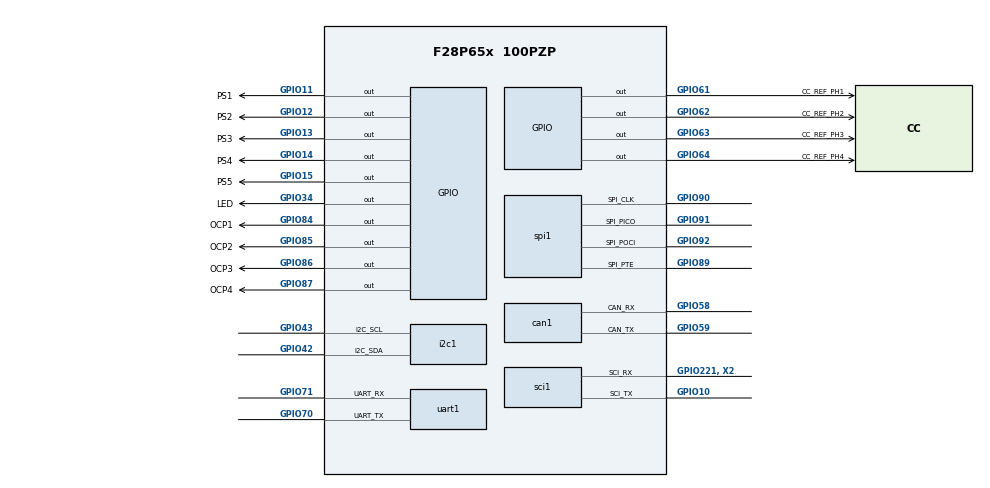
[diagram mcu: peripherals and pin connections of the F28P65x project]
/**
 * @cliArgs --device "F28P65x" --part "F28P65x_100PZP" --package "100PZP" --context "CPU1" --product "C2000WARE@6.00.01.00"
 * @versions {"tool":"1.26.0+4407"}
 */

/**
 * Import the modules used in this configuration.
 */
const adc              = scripting.addModule("/driverlib/adc.js", {}, false);
const adc1             = adc.addInstance();
const adc2             = adc.addInstance();
const adc3             = adc.addInstance();
const led              = scripting.addModule("/driverlib/board_components/led", {}, false);
const led1             = led.addInstance();
const can              = scripting.addModule("/driverlib/can.js", {}, false);
const can1             = can.addInstance();
const dac              = scripting.addModule("/driverlib/dac.js", {}, false);
const dac1             = dac.addInstance();
const dac2             = dac.addInstance();
const epwm             = scripting.addModule("/driverlib/epwm.js", {}, false);
const epwm1            = epwm.addInstance();
const epwm2            = epwm.addInstance();
const epwm3            = epwm.addInstance();
const epwm4            = epwm.addInstance();
const gpio             = scripting.addModule("/driverlib/gpio.js", {}, false);
const gpio2            = gpio.addInstance();
const gpio3            = gpio.addInstance();
const gpio4            = gpio.addInstance();
const gpio5            = gpio.addInstance();
const gpio6            = gpio.addInstance();
const gpio7            = gpio.addInstance();
const gpio8            = gpio.addInstance();
const gpio9            = gpio.addInstance();
const gpio10           = gpio.addInstance();
const gpio11           = gpio.addInstance();
const gpio12           = gpio.addInstance();
const gpio13           = gpio.addInstance();
const gpio14           = gpio.addInstance();
const gpio15           = gpio.addInstance();
const gpio16           = gpio.addInstance();
const gpio17           = gpio.addInstance();
const i2c              = scripting.addModule("/driverlib/i2c.js", {}, false);
const i2c1             = i2c.addInstance();
const inputxbar_input  = scripting.addModule("/driverlib/inputxbar_input.js", {}, false);
const inputxbar_input1 = inputxbar_input.addInstance();
const inputxbar_input2 = inputxbar_input.addInstance();
const inputxbar_input3 = inputxbar_input.addInstance();
const inputxbar_input4 = inputxbar_input.addInstance();
const inputxbar_input5 = inputxbar_input.addInstance();
const sci              = scripting.addModule("/driverlib/sci.js", {}, false);
const sci1             = sci.addInstance();
const spi              = scripting.addModule("/driverlib/spi.js", {}, false);
const spi1             = spi.addInstance();
const uart             = scripting.addModule("/driverlib/uart.js", {}, false);
const uart1            = uart.addInstance();
const uart2            = uart.addInstance();

/**
 * Write custom configuration values to the imported modules.
 */
adc1.$name             = "myADC0";
adc1.adcClockPrescaler = "ADC_CLK_DIV_3_5";
adc1.soc0SampleWindow  = 15;
adc1.soc1SampleWindow  = 15;
adc1.soc2SampleWindow  = 15;
adc1.soc3SampleWindow  = 15;
adc1.soc4SampleWindow  = 15;
adc1.soc0Channel       = "ADC_CH_ADCIN1";
adc1.soc1Channel       = "ADC_CH_ADCIN2";
adc1.soc2Channel       = "ADC_CH_ADCIN3";
adc1.soc3Channel       = "ADC_CH_ADCIN4";
adc1.soc4Channel       = "ADC_CH_ADCIN5";
adc1.enabledSOCs       = ["ADC_SOC_NUMBER0","ADC_SOC_NUMBER1","ADC_SOC_NUMBER2","ADC_SOC_NUMBER3","ADC_SOC_NUMBER4","ADC_SOC_NUMBER5","ADC_SOC_NUMBER6","ADC_SOC_NUMBER7"];
adc1.soc5Channel       = "ADC_CH_ADCIN6";
adc1.soc5SampleWindow  = 15;
adc1.soc6SampleWindow  = 15;
adc1.soc7SampleWindow  = 15;
adc1.soc6Channel       = "ADC_CH_ADCIN10";
adc1.soc7Channel       = "ADC_CH_ADCIN11";

adc2.$name             = "myADC1";
adc2.adcBase           = "ADCB_BASE";
adc2.adcClockPrescaler = "ADC_CLK_DIV_3_5";
adc2.soc0SampleWindow  = 15;
adc2.soc1SampleWindow  = 15;
adc2.soc2SampleWindow  = 15;
adc2.soc3SampleWindow  = 15;
adc2.soc1Channel       = "ADC_CH_ADCIN2";
adc2.soc2Channel       = "ADC_CH_ADCIN3";
adc2.soc3Channel       = "ADC_CH_ADCIN6";
adc2.enabledSOCs       = ["ADC_SOC_NUMBER0","ADC_SOC_NUMBER1","ADC_SOC_NUMBER2","ADC_SOC_NUMBER3","ADC_SOC_NUMBER4"];
adc2.soc4Channel       = "ADC_CH_ADCIN7";
adc2.soc4SampleWindow  = 15;

adc3.$name             = "myADC2";
adc3.adcClockPrescaler = "ADC_CLK_DIV_4_0";
adc3.adcResolutionMode = "ADC_RESOLUTION_16BIT";
adc3.adcSignalMode     = "ADC_MODE_DIFFERENTIAL";
adc3.enabledSOCs       = ["ADC_SOC_NUMBER0","ADC_SOC_NUMBER1","ADC_SOC_NUMBER2","ADC_SOC_NUMBER3"];
adc3.soc0Channel       = "ADC_CH_ADCIN0_ADCIN1";
adc3.soc0SampleWindow  = 65;
adc3.soc1Channel       = "ADC_CH_ADCIN2_ADCIN3";
adc3.soc1SampleWindow  = 65;
adc3.soc2Channel       = "ADC_CH_ADCIN4_ADCIN5";
adc3.soc2SampleWindow  = 65;
adc3.soc3Channel       = "ADC_CH_ADCIN14_ADCIN15";
adc3.soc3SampleWindow  = 65;
adc3.adcBase           = "ADCC_BASE";

led1.$name                = "LED";
led1.gpio.gpioPin.$assign = "GPIO34";

can1.$name                 = "myCAN0";
can1.can.$assign           = "CANA";
can1.can.can_rxPin.$assign = "GPIO58";
can1.can.can_txPin.$assign = "GPIO59";

const divider8       = system.clockTree["EPWMCLKDIV"];
divider8.divideValue = 1;

dac1.$name            = "myDAC0";
dac1.referenceVoltage = "DAC_REF_ADC_VREFHI";
dac1.enableOutput     = true;

dac2.$name            = "myDAC1";
dac2.dacBase          = "DACC_BASE";
dac2.enableOutput     = true;
dac2.referenceVoltage = "DAC_REF_ADC_VREFHI";

const analog  = scripting.addModule("/driverlib/analog.js", {}, false);
const analog1 = analog.addInstance({}, false);
analog1.$name = "myANALOGPinMux0";
adc1.analog   = analog1;
adc2.analog   = analog1;
adc3.analog   = analog1;
dac1.analog   = analog1;
dac2.analog   = analog1;

epwm1.$name                                                    = "myEPWM0";
epwm1.epwmTimebase_hsClockDiv                                  = "EPWM_HSCLOCK_DIVIDER_1";
epwm1.epwmTimebase_counterMode                                 = "EPWM_COUNTER_MODE_UP";
epwm1.epwmTimebase_period                                      = 10000;
epwm1.epwmCounterCompare_cmpA                                  = 5000;
epwm1.epwmActionQualifier_EPWM_AQ_OUTPUT_A_ON_TIMEBASE_ZERO    = "EPWM_AQ_OUTPUT_HIGH";
epwm1.epwmActionQualifier_EPWM_AQ_OUTPUT_A_ON_TIMEBASE_UP_CMPA = "EPWM_AQ_OUTPUT_LOW";
epwm1.epwmActionQualifier_EPWM_AQ_OUTPUT_B_ON_TIMEBASE_ZERO    = "EPWM_AQ_OUTPUT_HIGH";
epwm1.epwmActionQualifier_EPWM_AQ_OUTPUT_B_ON_TIMEBASE_UP_CMPB = "EPWM_AQ_OUTPUT_LOW";
epwm1.epwmCounterCompare_cmpB                                  = 5000;
epwm1.epwm.$assign                                             = "EPWM1";

epwm2.$name                                                    = "myEPWM1";
epwm2.copyUse                                                  = true;
epwm2.copyFrom                                                 = "myEPWM0";
epwm2.epwmTimebase_hsClockDiv                                  = "EPWM_HSCLOCK_DIVIDER_1";
epwm2.epwmTimebase_period                                      = 10000;
epwm2.epwmTimebase_counterMode                                 = "EPWM_COUNTER_MODE_UP";
epwm2.epwmCounterCompare_cmpA                                  = 5000;
epwm2.epwmCounterCompare_cmpB                                  = 5000;
epwm2.epwmActionQualifier_EPWM_AQ_OUTPUT_A_ON_TIMEBASE_ZERO    = "EPWM_AQ_OUTPUT_HIGH";
epwm2.epwmActionQualifier_EPWM_AQ_OUTPUT_A_ON_TIMEBASE_UP_CMPA = "EPWM_AQ_OUTPUT_LOW";
epwm2.epwmActionQualifier_EPWM_AQ_OUTPUT_B_ON_TIMEBASE_ZERO    = "EPWM_AQ_OUTPUT_HIGH";
epwm2.epwmActionQualifier_EPWM_AQ_OUTPUT_B_ON_TIMEBASE_UP_CMPB = "EPWM_AQ_OUTPUT_LOW";
epwm2.epwm.$assign                                             = "EPWM2";

epwm3.$name                                                    = "myEPWM2";
epwm3.copyUse                                                  = true;
epwm3.copyFrom                                                 = "myEPWM1";
epwm3.epwmTimebase_hsClockDiv                                  = "EPWM_HSCLOCK_DIVIDER_1";
epwm3.epwmTimebase_period                                      = 10000;
epwm3.epwmTimebase_counterMode                                 = "EPWM_COUNTER_MODE_UP";
epwm3.epwmCounterCompare_cmpA                                  = 5000;
epwm3.epwmCounterCompare_cmpB                                  = 5000;
epwm3.epwmActionQualifier_EPWM_AQ_OUTPUT_A_ON_TIMEBASE_ZERO    = "EPWM_AQ_OUTPUT_HIGH";
epwm3.epwmActionQualifier_EPWM_AQ_OUTPUT_A_ON_TIMEBASE_UP_CMPA = "EPWM_AQ_OUTPUT_LOW";
epwm3.epwmActionQualifier_EPWM_AQ_OUTPUT_B_ON_TIMEBASE_ZERO    = "EPWM_AQ_OUTPUT_HIGH";
epwm3.epwmActionQualifier_EPWM_AQ_OUTPUT_B_ON_TIMEBASE_UP_CMPB = "EPWM_AQ_OUTPUT_LOW";
epwm3.epwm.$assign                                             = "EPWM3";

epwm4.$name                                                    = "myEPWM3";
epwm4.copyUse                                                  = true;
epwm4.copyFrom                                                 = "myEPWM1";
epwm4.epwmTimebase_hsClockDiv                                  = "EPWM_HSCLOCK_DIVIDER_1";
epwm4.epwmTimebase_period                                      = 10000;
epwm4.epwmTimebase_counterMode                                 = "EPWM_COUNTER_MODE_UP";
epwm4.epwmCounterCompare_cmpA                                  = 5000;
epwm4.epwmCounterCompare_cmpB                                  = 5000;
epwm4.epwmActionQualifier_EPWM_AQ_OUTPUT_A_ON_TIMEBASE_ZERO    = "EPWM_AQ_OUTPUT_HIGH";
epwm4.epwmActionQualifier_EPWM_AQ_OUTPUT_A_ON_TIMEBASE_UP_CMPA = "EPWM_AQ_OUTPUT_LOW";
epwm4.epwmActionQualifier_EPWM_AQ_OUTPUT_B_ON_TIMEBASE_ZERO    = "EPWM_AQ_OUTPUT_HIGH";
epwm4.epwmActionQualifier_EPWM_AQ_OUTPUT_B_ON_TIMEBASE_UP_CMPB = "EPWM_AQ_OUTPUT_LOW";
epwm4.epwm.$assign                                             = "EPWM4";

gpio2.$name           = "PS1";
gpio2.padConfig       = "PULLUP";
gpio2.qualMode        = "GPIO_QUAL_ASYNC";
gpio2.gpioPin.$assign = "GPIO11";

gpio3.$name           = "PS3";
gpio3.padConfig       = "PULLUP";
gpio3.gpioPin.$assign = "GPIO13";

gpio4.$name           = "PS4";
gpio4.padConfig       = "PULLUP";
gpio4.gpioPin.$assign = "GPIO14";

gpio5.$name           = "PS5";
gpio5.padConfig       = "PULLUP";
gpio5.gpioPin.$assign = "GPIO15";

gpio6.$name           = "OCP1";
gpio6.padConfig       = "PULLUP";
gpio6.qualMode        = "GPIO_QUAL_ASYNC";
gpio6.gpioPin.$assign = "GPIO84";

gpio7.$name           = "OCP2";
gpio7.padConfig       = "PULLUP";
gpio7.qualMode        = "GPIO_QUAL_ASYNC";
gpio7.gpioPin.$assign = "GPIO85";

gpio8.$name           = "OCP3";
gpio8.padConfig       = "PULLUP";
gpio8.qualMode        = "GPIO_QUAL_ASYNC";
gpio8.gpioPin.$assign = "GPIO86";

gpio9.$name           = "OCP4";
gpio9.padConfig       = "PULLUP";
gpio9.qualMode        = "GPIO_QUAL_ASYNC";
gpio9.gpioPin.$assign = "GPIO87";

gpio10.$name           = "PS2";
gpio10.padConfig       = "PULLUP";
gpio10.qualMode        = "GPIO_QUAL_ASYNC";
gpio10.gpioPin.$assign = "GPIO12";

gpio11.$name           = "CC_REF_PH1";
gpio11.padConfig       = "PULLUP";
gpio11.gpioPin.$assign = "GPIO61";

gpio12.$name           = "CC_REF_PH2";
gpio12.padConfig       = "PULLUP";
gpio12.gpioPin.$assign = "GPIO62";

gpio13.$name           = "CC_REF_PH3";
gpio13.padConfig       = "PULLUP";
gpio13.gpioPin.$assign = "GPIO63";

gpio14.$name           = "CC_REF_PH4";
gpio14.padConfig       = "PULLUP";
gpio14.gpioPin.$assign = "GPIO64";

gpio15.$name             = "RELAY";
gpio15.writeInitialValue = true;
gpio15.direction         = "GPIO_DIR_MODE_OUT";

gpio16.$name     = "PFC";
gpio16.direction = "GPIO_DIR_MODE_OUT";

gpio17.$name = "myGPIO0";

i2c1.$name                  = "myI2C0";
i2c1.i2c.$assign            = "I2CA";
i2c1.i2c.i2c_sdaPin.$assign = "GPIO42";
i2c1.i2c.i2c_sclPin.$assign = "GPIO43";

inputxbar_input1.$name          = "myINPUTXBARINPUT0";
inputxbar_input1.inputxbarInput = "XBAR_INPUT4";
inputxbar_input1.inputxbarGpio  = "GPIO11";

inputxbar_input2.$name          = "myINPUTXBARINPUT1";
inputxbar_input2.inputxbarInput = "XBAR_INPUT5";
inputxbar_input2.inputxbarGpio  = "GPIO12";

inputxbar_input3.$name          = "myINPUTXBARINPUT2";
inputxbar_input3.inputxbarInput = "XBAR_INPUT6";
inputxbar_input3.inputxbarGpio  = "GPIO13";

inputxbar_input4.$name          = "myINPUTXBARINPUT3";
inputxbar_input4.inputxbarInput = "XBAR_INPUT13";
inputxbar_input4.inputxbarGpio  = "GPIO14";

inputxbar_input5.$name          = "myINPUTXBARINPUT4";
inputxbar_input5.inputxbarInput = "XBAR_INPUT14";
inputxbar_input5.inputxbarGpio  = "GPIO15";

sci1.$name                 = "mySCI0";
sci1.sci.$assign           = "SCIB";
sci1.sci.sci_rxPin.$assign = "GPIO221, X2";
sci1.sci.sci_txPin.$assign = "GPIO10";
sci1.rxQual.$name          = "myGPIOQUAL0";
sci1.txQual.$name          = "myGPIOQUAL1";

spi1.$name                   = "mySPI0";
spi1.spi.$assign             = "SPID";
spi1.spi.spi_picoPin.$assign = "GPIO91";
spi1.spi.spi_pociPin.$assign = "GPIO92";
spi1.spi.spi_clkPin.$assign  = "GPIO90";
spi1.spi.spi_ptePin.$assign  = "GPIO89";
spi1.picoQual.$name          = "myGPIOQUAL6";
spi1.pociQual.$name          = "myGPIOQUAL7";
spi1.clkQual.$name           = "myGPIOQUAL8";
spi1.pteQual.$name           = "myGPIOQUAL9";

uart1.$name                   = "myUART0";
uart1.uart.$assign            = "UARTB";
uart1.uart.uart_txPin.$assign = "GPIO70";
uart1.uart.uart_rxPin.$assign = "GPIO71";
uart1.txQual.$name            = "myGPIOQUAL2";
uart1.rxQual.$name            = "myGPIOQUAL3";

uart2.$name        = "myUART1";
uart2.uart.$assign = "UARTA";
uart2.txQual.$name = "myGPIOQUAL4";
uart2.rxQual.$name = "myGPIOQUAL5";

/**
 * Pinmux solution for unlocked pins/peripherals. This ensures that minor changes to the automatic solver in a future
 * version of the tool will not impact the pinmux you originally saw.  These lines can be completely deleted in order to
 * re-solve from scratch.
 */
analog1.analog.$suggestSolution                    = "ANALOG";
analog1.analog["a0/daca_outPin"].$suggestSolution  = "A0/DACA_OUT";
analog1.analog.a1Pin.$suggestSolution              = "A1";
analog1.analog["a10, gpio213Pin"].$suggestSolution = "A10, GPIO213";
analog1.analog["a11, gpio214Pin"].$suggestSolution = "A11, GPIO214";
analog1.analog["a14/b14/c14Pin"].$suggestSolution  = "A14/B14/C14";
analog1.analog["a15/b15/c15Pin"].$suggestSolution  = "A15/B15/C15";
analog1.analog.a2Pin.$suggestSolution              = "A2";
analog1.analog.a3Pin.$suggestSolution              = "A3";
analog1.analog.a4Pin.$suggestSolution              = "A4";
analog1.analog.a5Pin.$suggestSolution              = "A5";
analog1.analog["a6, gpio209Pin"].$suggestSolution  = "A6, GPIO209";
analog1.analog["b0/vdacPin"].$suggestSolution      = "B0/VDAC";
analog1.analog["b1/dacc_outPin"].$suggestSolution  = "B1/DACC_OUT";
analog1.analog.b2Pin.$suggestSolution              = "B2";
analog1.analog.b3Pin.$suggestSolution              = "B3";
analog1.analog["b6, gpio207Pin"].$suggestSolution  = "B6, GPIO207";
analog1.analog["b7, gpio208Pin"].$suggestSolution  = "B7, GPIO208";
analog1.analog["c0, gpio199Pin"].$suggestSolution  = "C0, GPIO199";
analog1.analog.c2Pin.$suggestSolution              = "C2";
analog1.analog["c3, gpio206Pin"].$suggestSolution  = "C3, GPIO206";
analog1.analog["c4, gpio205Pin"].$suggestSolution  = "C4, GPIO205";
analog1.analog["c5, gpio204Pin"].$suggestSolution  = "C5, GPIO204";
analog1.analog["c6, gpio203Pin"].$suggestSolution  = "C6, GPIO203";
analog1.analog["c1, gpio200Pin"].$suggestSolution  = "C1, GPIO200";
epwm1.epwm.epwm_aPin.$suggestSolution              = "GPIO0";
epwm1.epwm.epwm_bPin.$suggestSolution              = "GPIO1";
epwm2.epwm.epwm_aPin.$suggestSolution              = "GPIO2";
epwm2.epwm.epwm_bPin.$suggestSolution              = "GPIO3";
epwm3.epwm.epwm_aPin.$suggestSolution              = "GPIO4";
epwm3.epwm.epwm_bPin.$suggestSolution              = "GPIO60";
epwm4.epwm.epwm_aPin.$suggestSolution              = "GPIO46";
epwm4.epwm.epwm_bPin.$suggestSolution              = "GPIO47";
gpio15.gpioPin.$suggestSolution                    = "GPIO100";
gpio16.gpioPin.$suggestSolution                    = "GPIO35";
gpio17.gpioPin.$suggestSolution                    = "GPIO222/TDI";
uart2.uart.uart_txPin.$suggestSolution             = "GPIO72";
uart2.uart.uart_rxPin.$suggestSolution             = "GPIO73";
